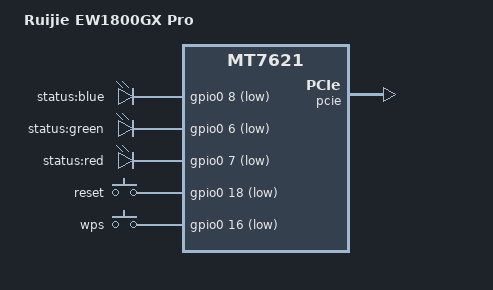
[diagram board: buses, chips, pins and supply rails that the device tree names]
/dts-v1/;

#include "mt7621.dtsi"
#include <dt-bindings/input/input.h>
#include "mt7621-spi-16m-layout.dtsi"
#include "mt7621-raeth-gmac2.dtsi"
#include "mt7621-pinctrl-default-gpio.dtsi"

/ {
	compatible = "mediatek,mt7621-soc";
	model = "Ruijie EW1800GX Pro";

	aliases {
		led-boot = &led_status;
		led-failsafe = &led_status;
		led-running = &led_status;
		led-upgrade = &led_status;
	};
	
	chosen {
		bootargs = "console=ttyS0,115200";
	};

	leds {
		compatible = "gpio-leds";

		led_status: status {
			label = "status:blue";
			gpios = <&gpio0 8 GPIO_ACTIVE_LOW>;
		};

		led_green: green {
			label = "status:green";
			gpios = <&gpio0 6 GPIO_ACTIVE_LOW>;
		};

		led_red: red {
			label = "status:red";
			gpios = <&gpio0 7 GPIO_ACTIVE_LOW>;
		};
	};

	gpio-keys-polled {
		compatible = "gpio-keys-polled";
		#address-cells = <1>;
		#size-cells = <0>;
		poll-interval = <20>;

		reset {
			label = "reset";
			gpios = <&gpio0 18 GPIO_ACTIVE_LOW>;
			linux,code = <KEY_RESTART>;
		};
		
		wps {
			label = "wps";
			gpios = <&gpio0 16 GPIO_ACTIVE_LOW>;
			linux,code = <KEY_WPS_BUTTON>;
		};
	};
};

&pcie {
	status = "okay";
};
